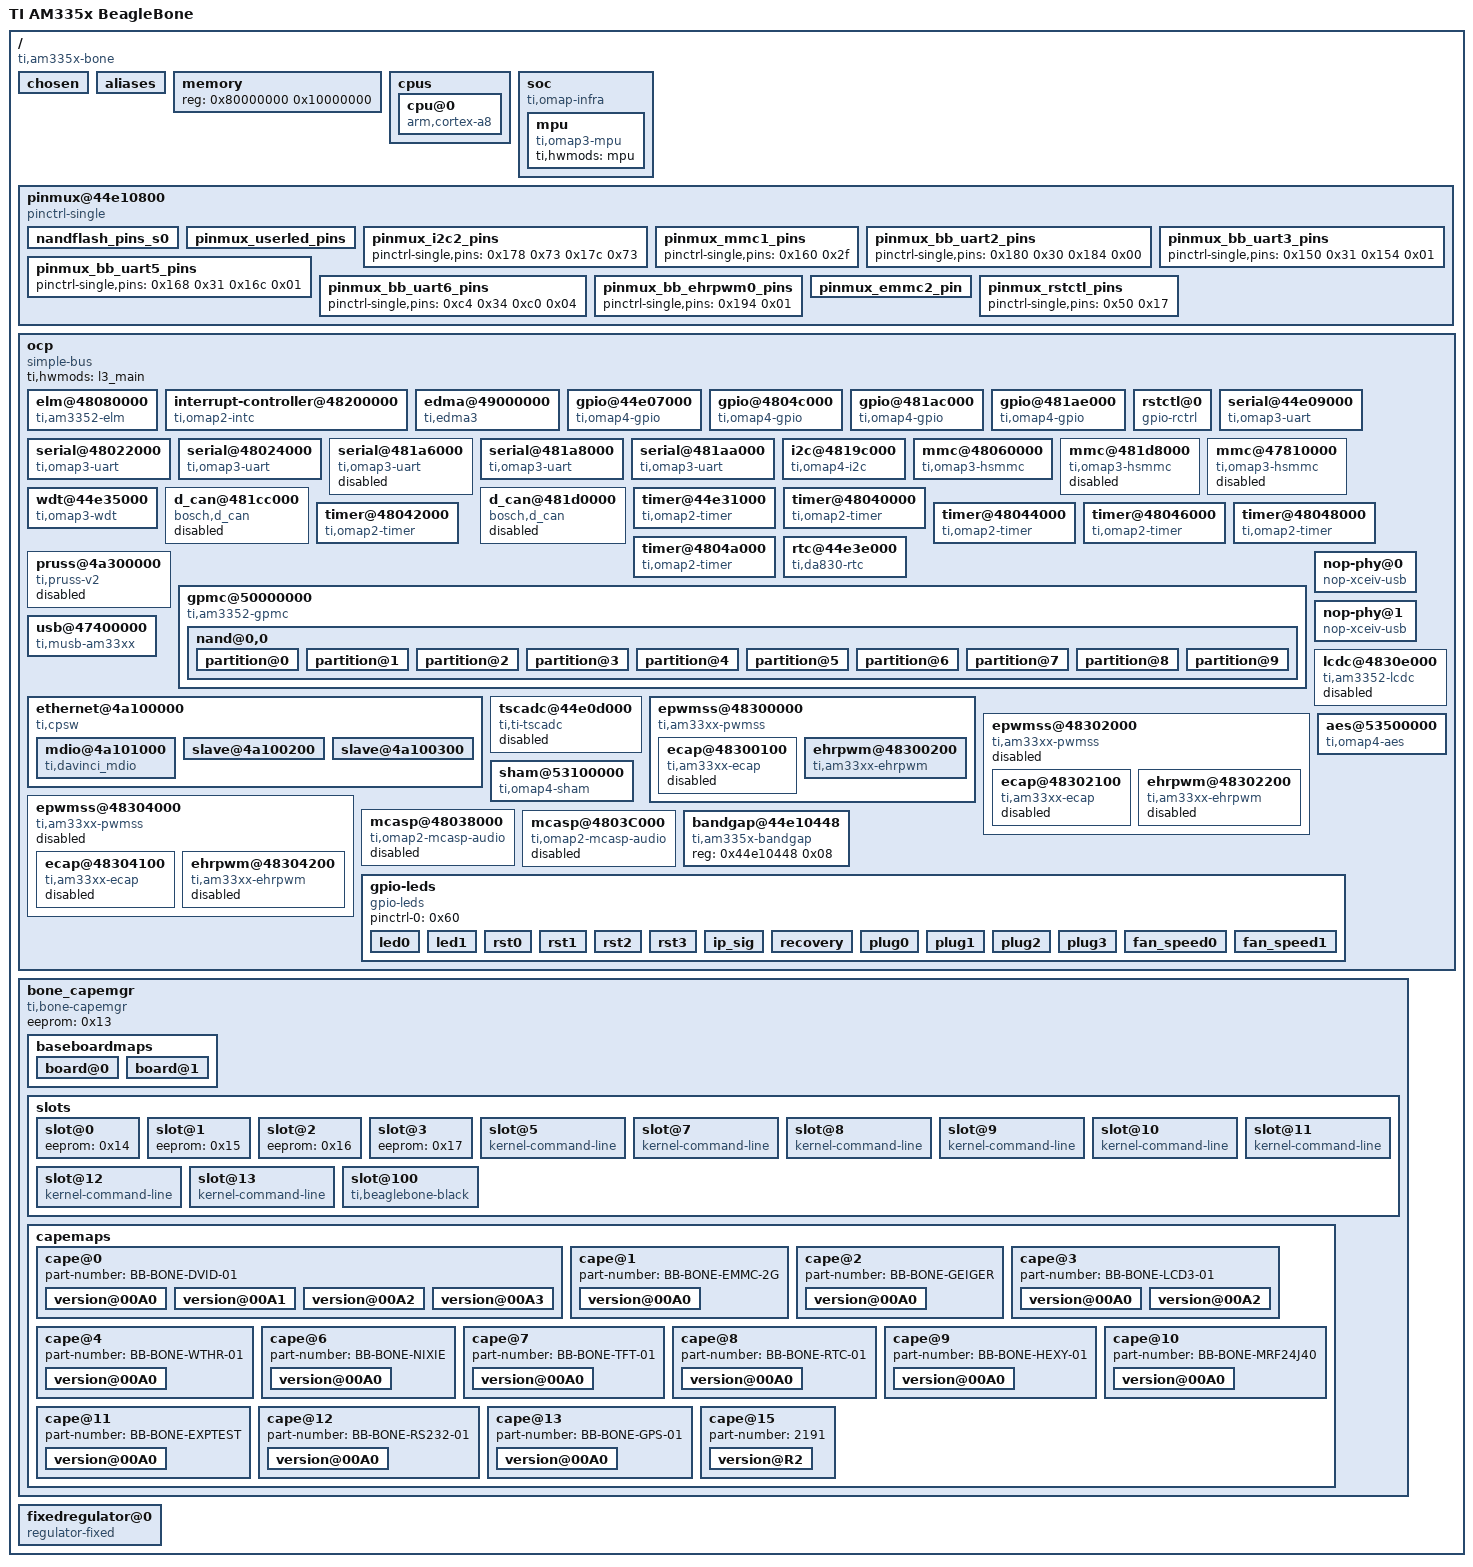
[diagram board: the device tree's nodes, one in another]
/dts-v1/;

/ {
	#address-cells = <0x01>;
	#size-cells = <0x01>;
	compatible = "ti,am335x-bone\0ti,am33xx";
	interrupt-parent = <0x01>;
	model = "TI AM335x BeagleBone";

	chosen {
	};

	aliases {
		serial0 = "/ocp/serial@44e09000";
		serial1 = "/ocp/serial@48022000";
		serial2 = "/ocp/serial@48024000";
		serial3 = "/ocp/serial@481a6000";
		serial4 = "/ocp/serial@481a8000";
		serial5 = "/ocp/serial@481aa000";
	};

	memory {
		device_type = "memory";
		reg = <0x80000000 0x10000000>;
	};

	cpus {

		cpu@0 {
			compatible = "arm,cortex-a8";
			operating-points = <0xf4240 0x149970 0xc3500 0x13d620 0x927c0 0x10f7c0 0x493e0 0xec928>;
			voltage-tolerance = <0x02>;
			clock-latency = <0x493e0>;
			cpu0-supply = <0x02>;
		};
	};

	soc {
		compatible = "ti,omap-infra";

		mpu {
			compatible = "ti,omap3-mpu";
			ti,hwmods = "mpu";
		};
	};

	pinmux@44e10800 {
		compatible = "pinctrl-single";
		reg = <0x44e10800 0x238>;
		#address-cells = <0x01>;
		#size-cells = <0x00>;
		pinctrl-single,register-width = <0x20>;
		pinctrl-single,function-mask = <0x7f>;
		pinctrl-names = "default";
		pinctrl-0 = <0x03>;

		nandflash_pins_s0 {
			pinctrl-single,pins = <0x00 0x30 0x04 0x30 0x08 0x30 0x0c 0x30 0x10 0x30 0x14 0x30 0x18 0x30 0x1c 0x30 0x70 0x30 0x74 0x37 0x7c 0x08 0x90 0x08 0x94 0x08 0x98 0x08 0x9c 0x08>;
		};

		pinmux_userled_pins {
			pinctrl-single,pins = <0x24 0x27 0x34 0x27 0x158 0x27 0x15c 0x27 0x20 0x27 0x2c 0x27 0x28 0x37 0x38 0x37 0x4c 0x27 0x40 0x27 0x3c 0x27 0x30 0x27 0x198 0x27 0x190 0x27>;
			linux,phandle = <0x60>;
			phandle = <0x60>;
		};

		pinmux_i2c2_pins {
			pinctrl-single,pins = <0x178 0x73 0x17c 0x73>;
			linux,phandle = <0x07>;
			phandle = <0x07>;
		};

		pinmux_mmc1_pins {
			pinctrl-single,pins = <0x160 0x2f>;
			linux,phandle = <0x0a>;
			phandle = <0x0a>;
		};

		pinmux_bb_uart2_pins {
			pinctrl-single,pins = <0x180 0x30 0x184 0x00>;
			linux,phandle = <0x51>;
			phandle = <0x51>;
		};

		pinmux_bb_uart3_pins {
			pinctrl-single,pins = <0x150 0x31 0x154 0x01>;
			linux,phandle = <0x52>;
			phandle = <0x52>;
		};

		pinmux_bb_uart5_pins {
			pinctrl-single,pins = <0x168 0x31 0x16c 0x01>;
			linux,phandle = <0x53>;
			phandle = <0x53>;
		};

		pinmux_bb_uart6_pins {
			pinctrl-single,pins = <0xc4 0x34 0xc0 0x04>;
			linux,phandle = <0x54>;
			phandle = <0x54>;
		};

		pinmux_bb_ehrpwm0_pins {
			pinctrl-single,pins = <0x194 0x01>;
			linux,phandle = <0x64>;
			phandle = <0x64>;
		};

		pinmux_emmc2_pin {
			pinctrl-single,pins = <0x80 0x32 0x84 0x32 0x00 0x31 0x04 0x31 0x08 0x31 0x0c 0x31 0x10 0x31 0x14 0x31 0x18 0x31 0x1c 0x31>;
			linux,phandle = <0x0d>;
			phandle = <0x0d>;
		};

		pinmux_rstctl_pins {
			pinctrl-single,pins = <0x50 0x17>;
			linux,phandle = <0x04>;
			phandle = <0x04>;
		};
	};

	ocp {
		compatible = "simple-bus";
		#address-cells = <0x01>;
		#size-cells = <0x01>;
		ranges;
		ti,hwmods = "l3_main";

		elm@48080000 {
			compatible = "ti,am3352-elm";
			reg = <0x48080000 0x2000>;
			interrupts = <0x04>;
			ti,hwmods = "elm";
			clock-names = "fck";
			status = "okay";
			linux,phandle = <0x10>;
			phandle = <0x10>;
		};

		interrupt-controller@48200000 {
			compatible = "ti,omap2-intc";
			interrupt-controller;
			#interrupt-cells = <0x01>;
			ti,intc-size = <0x80>;
			reg = <0x48200000 0x1000>;
			linux,phandle = <0x01>;
			phandle = <0x01>;
		};

		edma@49000000 {
			compatible = "ti,edma3";
			ti,hwmods = "tpcc\0tptc0\0tptc1\0tptc2";
			reg = <0x49000000 0x10000 0x44e10f90 0x40>;
			interrupt-parent = <0x01>;
			interrupts = <0x0c 0x0d 0x0e>;
			#dma-cells = <0x01>;
			dma-channels = <0x40>;
			ti,edma-regions = <0x04>;
			ti,edma-slots = <0x100>;
			ti,edma-queue-tc-map = <0x00 0x00 0x01 0x01 0x02 0x02>;
			ti,edma-queue-priority-map = <0x00 0x00 0x01 0x01 0x02 0x02>;
			ti,edma-default-queue = <0x01>;
			ti,edma-xbar-event-map = <0x20 0x0c 0x1e 0x14>;
			linux,phandle = <0x09>;
			phandle = <0x09>;
		};

		gpio@44e07000 {
			compatible = "ti,omap4-gpio";
			ti,hwmods = "gpio1";
			gpio-controller;
			#gpio-cells = <0x02>;
			interrupt-controller;
			#interrupt-cells = <0x01>;
			reg = <0x44e07000 0x1000>;
			interrupts = <0x60>;
			linux,phandle = <0x0b>;
			phandle = <0x0b>;
		};

		gpio@4804c000 {
			compatible = "ti,omap4-gpio";
			ti,hwmods = "gpio2";
			gpio-controller;
			#gpio-cells = <0x02>;
			interrupt-controller;
			#interrupt-cells = <0x01>;
			reg = <0x4804c000 0x1000>;
			interrupts = <0x62>;
			linux,phandle = <0x05>;
			phandle = <0x05>;
		};

		gpio@481ac000 {
			compatible = "ti,omap4-gpio";
			ti,hwmods = "gpio3";
			gpio-controller;
			#gpio-cells = <0x02>;
			interrupt-controller;
			#interrupt-cells = <0x01>;
			reg = <0x481ac000 0x1000>;
			interrupts = <0x20>;
			linux,phandle = <0x70>;
			phandle = <0x70>;
		};

		gpio@481ae000 {
			compatible = "ti,omap4-gpio";
			ti,hwmods = "gpio4";
			gpio-controller;
			#gpio-cells = <0x02>;
			interrupt-controller;
			#interrupt-cells = <0x01>;
			reg = <0x481ae000 0x1000>;
			interrupts = <0x3e>;
			linux,phandle = <0x71>;
			phandle = <0x71>;
		};

		rstctl@0 {
			status = "okay";
			compatible = "gpio-rctrl";
			pinctrl-names = "default";
			pinctrl-0 = <0x04>;
			#reset-cells = <0x02>;
			gpios = <0x05 0x14 0x00>;
			gpio-names = "eMMC_RSTn";
			linux,phandle = <0x0f>;
			phandle = <0x0f>;
		};

		serial@44e09000 {
			compatible = "ti,omap3-uart";
			ti,hwmods = "uart1";
			clock-frequency = <0x2dc6c00>;
			reg = <0x44e09000 0x2000>;
			interrupts = <0x48>;
			status = "okay";
		};

		serial@48022000 {
			compatible = "ti,omap3-uart";
			ti,hwmods = "uart2";
			clock-frequency = <0x2dc6c00>;
			reg = <0x48022000 0x2000>;
			interrupts = <0x49>;
			status = "okay";
			pinctrl-names = "default";
			pinctrl-0 = <0x51>;
		};

		serial@48024000 {
			compatible = "ti,omap3-uart";
			ti,hwmods = "uart3";
			clock-frequency = <0x2dc6c00>;
			reg = <0x48024000 0x2000>;
			interrupts = <0x4a>;
			status = "okay";
			pinctrl-names = "default";
			pinctrl-0 = <0x52>;
		};

		serial@481a6000 {
			compatible = "ti,omap3-uart";
			ti,hwmods = "uart4";
			clock-frequency = <0x2dc6c00>;
			reg = <0x481a6000 0x2000>;
			interrupts = <0x2c>;
			status = "disabled";
		};

		serial@481a8000 {
			compatible = "ti,omap3-uart";
			ti,hwmods = "uart5";
			clock-frequency = <0x2dc6c00>;
			reg = <0x481a8000 0x2000>;
			interrupts = <0x2d>;
			status = "okay";
			pinctrl-names = "default";
			pinctrl-0 = <0x53>;
		};

		serial@481aa000 {
			compatible = "ti,omap3-uart";
			ti,hwmods = "uart6";
			clock-frequency = <0x2dc6c00>;
			reg = <0x481aa000 0x2000>;
			interrupts = <0x2e>;
			status = "okay";
			pinctrl-names = "default";
			pinctrl-0 = <0x54>;
		};

		i2c@4819c000 {
			compatible = "ti,omap4-i2c";
			#address-cells = <0x01>;
			#size-cells = <0x00>;
			ti,hwmods = "i2c3";
			reg = <0x4819c000 0x1000>;
			interrupts = <0x1e>;
			status = "okay";
			pinctrl-names = "default";
			pinctrl-0 = <0x07>;
			clock-frequency = <0x186a0>;
		};

		mmc@48060000 {
			compatible = "ti,omap3-hsmmc";
			ti,hwmods = "mmc1";
			ti,dual-volt;
			ti,needs-special-reset;
			ti,needs-special-hs-handling;
			dmas = <0x09 0x18 0x09 0x19>;
			dma-names = "tx\0rx";
			status = "okay";
			pinctrl-names = "default";
			pinctrl-0 = <0x0a>;
			cd-gpios = <0x0b 0x06 0x00>;
			cd-inverted;
			vmmc-supply = <0x0c>;
			ti,vcc-aux-disable-is-sleep;
		};

		mmc@481d8000 {
			compatible = "ti,omap3-hsmmc";
			ti,hwmods = "mmc2";
			ti,needs-special-reset;
			ti,needs-special-hs-handling;
			dmas = <0x09 0x02 0x09 0x03>;
			dma-names = "tx\0rx";
			status = "disabled";
		};

		mmc@47810000 {
			compatible = "ti,omap3-hsmmc";
			ti,hwmods = "mmc3";
			ti,needs-special-reset;
			ti,needs-special-hs-handling;
			status = "disabled";
		};

		wdt@44e35000 {
			compatible = "ti,omap3-wdt";
			ti,hwmods = "wd_timer2";
			reg = <0x44e35000 0x1000>;
			interrupts = <0x5b>;
		};

		d_can@481cc000 {
			compatible = "bosch,d_can";
			ti,hwmods = "d_can0";
			reg = <0x481cc000 0x2000>;
			interrupts = <0x34>;
			status = "disabled";
		};

		d_can@481d0000 {
			compatible = "bosch,d_can";
			ti,hwmods = "d_can1";
			reg = <0x481d0000 0x2000>;
			interrupts = <0x37>;
			status = "disabled";
		};

		timer@44e31000 {
			compatible = "ti,omap2-timer";
			reg = <0x44e31000 0x400>;
			interrupts = <0x43>;
			ti,hwmods = "timer1";
			ti,timer-alwon;
		};

		timer@48040000 {
			compatible = "ti,omap2-timer";
			reg = <0x48040000 0x400>;
			interrupts = <0x44>;
			ti,hwmods = "timer2";
		};

		timer@48042000 {
			compatible = "ti,omap2-timer";
			reg = <0x48042000 0x400>;
			interrupts = <0x45>;
			ti,hwmods = "timer3";
		};

		timer@48044000 {
			compatible = "ti,omap2-timer";
			reg = <0x48044000 0x400>;
			interrupts = <0x5c>;
			ti,hwmods = "timer4";
			ti,timer-pwm;
		};

		timer@48046000 {
			compatible = "ti,omap2-timer";
			reg = <0x48046000 0x400>;
			interrupts = <0x5d>;
			ti,hwmods = "timer5";
			ti,timer-pwm;
		};

		timer@48048000 {
			compatible = "ti,omap2-timer";
			reg = <0x48048000 0x400>;
			interrupts = <0x5e>;
			ti,hwmods = "timer6";
			ti,timer-pwm;
		};

		timer@4804a000 {
			compatible = "ti,omap2-timer";
			reg = <0x4804a000 0x400>;
			interrupts = <0x5f>;
			ti,hwmods = "timer7";
			ti,timer-pwm;
		};

		pruss@4a300000 {
			compatible = "ti,pruss-v2";
			ti,hwmods = "pruss";
			ti,deassert-hard-reset = "pruss\0pruss";
			reg = <0x4a300000 0x80000>;
			ti,pintc-offset = <0x20000>;
			interrupt-parent = <0x01>;
			status = "disabled";
			interrupts = <0x14 0x15 0x16 0x17 0x18 0x19 0x1a 0x1b>;
		};

		rtc@44e3e000 {
			compatible = "ti,da830-rtc";
			reg = <0x44e3e000 0x1000>;
			interrupts = <0x4b 0x4c>;
			ti,hwmods = "rtc";
			ti,system-power-controller;
		};

		gpmc@50000000 {
			compatible = "ti,am3352-gpmc";
			ti,hwmods = "gpmc";
			reg = <0x50000000 0x1000000>;
			interrupts = <0x64>;
			gpmc,num-cs = <0x07>;
			gpmc,num-waitpins = <0x02>;
			#address-cells = <0x02>;
			#size-cells = <0x01>;
			status = "okay";
			pinctrl-names = "default";
			pinctrl-0 = <0x0f>;
			ranges = <0x00 0x00 0x8000000 0x10000000>;

			nand@0,0 {
				gpmc,device-nand;
				reg = <0x00 0x00 0x00>;
				nand-bus-width = <0x08>;
				gpmc,device-width = <0x01>;
				gpmc,sync-clk-ps = <0x00>;
				gpmc,cs-on-ns = <0x00>;
				gpmc,cs-rd-off-ns = <0x118>;
				gpmc,cs-wr-off-ns = <0x118>;
				gpmc,adv-on-ns = <0x32>;
				gpmc,adv-rd-off-ns = <0x118>;
				gpmc,adv-wr-off-ns = <0x118>;
				gpmc,we-on-ns = <0x32>;
				gpmc,we-off-ns = <0xc8>;
				gpmc,oe-on-ns = <0x32>;
				gpmc,oe-off-ns = <0x96>;
				gpmc,access-ns = <0xc8>;
				gpmc,rd-cycle-ns = <0x12c>;
				gpmc,wr-cycle-ns = <0x12c>;
				gpmc,wait-on-read = "true";
				gpmc,wait-on-write = "true";
				gpmc,bus-turnaround-ns = <0x00>;
				gpmc,cycle2cycle-delay-ns = <0x78>;
				gpmc,cycle2cycle-samecsen = "true";
				gpmc,clk-activation-ns = <0x00>;
				gpmc,wait-monitoring-ns = <0x00>;
				gpmc,wr-access-ns = <0x28>;
				gpmc,wr-data-mux-bus-ns = <0x00>;
				ti,nand-ecc-opt = "bch8";
				ti,elm-id = <0x10>;
				#address-cells = <0x01>;
				#size-cells = <0x01>;

				partition@0 {
					label = "spl";
					reg = <0x00 0x20000>;
				};

				partition@1 {
					label = "spl_backup1";
					reg = <0x20000 0x20000>;
				};

				partition@2 {
					label = "spl_backup2";
					reg = <0x40000 0x20000>;
				};

				partition@3 {
					label = "spl_backup3";
					reg = <0x60000 0x20000>;
				};

				partition@4 {
					label = "u-boot";
					reg = <0x80000 0x1c0000>;
				};

				partition@5 {
					label = "bootenv";
					reg = <0x240000 0x20000>;
				};

				partition@6 {
					label = "fdt";
					reg = <0x260000 0x20000>;
				};

				partition@7 {
					label = "kernel";
					reg = <0x280000 0x500000>;
				};

				partition@8 {
					label = "root";
					reg = <0x800000 0x1400000>;
				};

				partition@9 {
					label = "config";
					reg = <0x1c00000 0x1400000>;
				};
			};
		};

		nop-phy@0 {
			compatible = "nop-xceiv-usb";
		};

		nop-phy@1 {
			compatible = "nop-xceiv-usb";
		};

		usb@47400000 {
			compatible = "ti,musb-am33xx";
			reg = <0x47400000 0x1000 0x47401000 0x800 0x47401800 0x800>;
			interrupts = <0x11 0x12 0x13>;
			multipoint = <0x01>;
			num-eps = <0x10>;
			ram-bits = <0x0c>;
			port0-mode = <0x03>;
			port1-mode = <0x01>;
			power = <0xfa>;
			ti,hwmods = "usb_otg_hs";
			status = "okay";
			interface_type = <0x01>;
		};

		ethernet@4a100000 {
			compatible = "ti,cpsw";
			ti,hwmods = "cpgmac0";
			cpdma_channels = <0x08>;
			ale_entries = <0x400>;
			bd_ram_size = <0x2000>;
			no_bd_ram = <0x00>;
			rx_descs = <0x40>;
			mac_control = <0x20>;
			slaves = <0x02>;
			cpts_active_slave = <0x00>;
			cpts_clock_mult = <0x80000000>;
			cpts_clock_shift = <0x1d>;
			reg = <0x4a100000 0x800 0x4a101200 0x100>;
			#address-cells = <0x01>;
			#size-cells = <0x01>;
			interrupt-parent = <0x01>;
			interrupts = <0x28 0x29 0x2a 0x2b>;
			ranges;
			disable-napi;

			mdio@4a101000 {
				compatible = "ti,davinci_mdio";
				#address-cells = <0x01>;
				#size-cells = <0x00>;
				ti,hwmods = "davinci_mdio";
				bus_freq = <0xf4240>;
				reg = <0x4a101000 0x100>;
				linux,phandle = <0x12>;
				phandle = <0x12>;
			};

			slave@4a100200 {
				mac-address = [00 00 00 00 00 00];
				phy_id = <0x12 0x00>;
			};

			slave@4a100300 {
				mac-address = [00 00 00 00 00 00];
				phy_id = <0x12 0x01>;
			};
		};

		tscadc@44e0d000 {
			compatible = "ti,ti-tscadc";
			reg = <0x44e0d000 0x1000>;
			interrupt-parent = <0x01>;
			interrupts = <0x10>;
			ti,hwmods = "adc_tsc";
			status = "disabled";
		};

		lcdc@4830e000 {
			compatible = "ti,am3352-lcdc\0ti,da830-lcdc";
			reg = <0x4830e000 0x1000>;
			interrupts = <0x24>;
			status = "disabled";
			ti,hwmods = "lcdc";
		};

		epwmss@48300000 {
			compatible = "ti,am33xx-pwmss";
			reg = <0x48300000 0x10>;
			ti,hwmods = "epwmss0";
			#address-cells = <0x01>;
			#size-cells = <0x01>;
			status = "okay";
			ranges = <0x48300100 0x48300100 0x80 0x48300180 0x48300180 0x80 0x48300200 0x48300200 0x80>;

			ecap@48300100 {
				compatible = "ti,am33xx-ecap";
				#pwm-cells = <0x03>;
				reg = <0x48300100 0x80>;
				ti,hwmods = "ecap0";
				status = "disabled";
			};

			ehrpwm@48300200 {
				compatible = "ti,am33xx-ehrpwm";
				#pwm-cells = <0x03>;
				reg = <0x48300200 0x60>;
				ti,hwmods = "ehrpwm0";
				status = "okay";
				pinctrl-names = "default";
				pinctrl-0 = <0x64>;
			};
		};

		epwmss@48302000 {
			compatible = "ti,am33xx-pwmss";
			reg = <0x48302000 0x10>;
			ti,hwmods = "epwmss1";
			#address-cells = <0x01>;
			#size-cells = <0x01>;
			status = "disabled";
			ranges = <0x48302100 0x48302100 0x80 0x48302180 0x48302180 0x80 0x48302200 0x48302200 0x80>;

			ecap@48302100 {
				compatible = "ti,am33xx-ecap";
				#pwm-cells = <0x03>;
				reg = <0x48302100 0x80>;
				ti,hwmods = "ecap1";
				status = "disabled";
			};

			ehrpwm@48302200 {
				compatible = "ti,am33xx-ehrpwm";
				#pwm-cells = <0x03>;
				reg = <0x48302200 0x80>;
				ti,hwmods = "ehrpwm1";
				status = "disabled";
			};
		};

		epwmss@48304000 {
			compatible = "ti,am33xx-pwmss";
			reg = <0x48304000 0x10>;
			ti,hwmods = "epwmss2";
			#address-cells = <0x01>;
			#size-cells = <0x01>;
			status = "disabled";
			ranges = <0x48304100 0x48304100 0x80 0x48304180 0x48304180 0x80 0x48304200 0x48304200 0x80>;

			ecap@48304100 {
				compatible = "ti,am33xx-ecap";
				#pwm-cells = <0x03>;
				reg = <0x48304100 0x80>;
				ti,hwmods = "ecap2";
				status = "disabled";
			};

			ehrpwm@48304200 {
				compatible = "ti,am33xx-ehrpwm";
				#pwm-cells = <0x03>;
				reg = <0x48304200 0x80>;
				ti,hwmods = "ehrpwm2";
				status = "disabled";
			};
		};

		sham@53100000 {
			compatible = "ti,omap4-sham";
			ti,hwmods = "sham";
			#address-cells = <0x01>;
			#size-cells = <0x00>;
			reg = <0x53100000 0x200>;
			interrupt-parent = <0x01>;
			interrupts = <0x6d>;
			dmas = <0x09 0x24>;
			dma-names = "rx";
			status = "okay";
		};

		aes@53500000 {
			compatible = "ti,omap4-aes";
			ti,hwmods = "aes";
			#address-cells = <0x01>;
			#size-cells = <0x00>;
			reg = <0x53500000 0xa0>;
			interrupt-parent = <0x01>;
			interrupts = <0x66>;
			dmas = <0x09 0x06 0x09 0x05>;
			dma-names = "tx\0rx";
			status = "okay";
		};

		mcasp@48038000 {
			compatible = "ti,omap2-mcasp-audio";
			#address-cells = <0x01>;
			#size-cells = <0x00>;
			ti,hwmods = "mcasp0";
			reg = <0x48038000 0x2000>;
			interrupts = <0x50 0x51>;
			status = "disabled";
			asp-chan-q = <0x02>;
			tx-dma-offset = <0x46000000>;
			rx-dma-offset = <0x46000000>;
			dmas = <0x09 0x08 0x09 0x09>;
			dma-names = "tx\0rx";
		};

		mcasp@4803C000 {
			compatible = "ti,omap2-mcasp-audio";
			#address-cells = <0x01>;
			#size-cells = <0x00>;
			ti,hwmods = "mcasp1";
			reg = <0x4803c000 0x2000>;
			interrupts = <0x52 0x53>;
			status = "disabled";
			asp-chan-q = <0x02>;
			tx-dma-offset = "F@\0";
			rx-dma-offset = "F@\0";
			dmas = <0x09 0x0a 0x09 0x0b>;
			dma-names = "tx\0rx";
		};

		bandgap@44e10448 {
			compatible = "ti,am335x-bandgap";
			reg = <0x44e10448 0x08>;
		};

		gpio-leds {
			compatible = "gpio-leds";
			pinctrl-names = "default";
			pinctrl-0 = <0x60>;

			led0 {
				label = "Green";
				gpios = <0x0b 0x23 0x01>;
				default-state = "on";
			};

			led1 {
				label = "Red";
				gpios = <0x05 0x13 0x01>;
				default-state = "on";
			};

			rst0 {
				label = "rst0";
				gpios = <0x0b 0x05 0x01>;
				default-state = "on";
			};

			rst1 {
				label = "res1";
				gpios = <0x0b 0x04 0x01>;
				default-state = "on";
			};

			rst2 {
				label = "rst2";
				gpios = <0x0b 0x27 0x01>;
				default-state = "on";
			};

			rst3 {
				label = "rst3";
				gpios = <0x0b 0x22 0x01>;
				default-state = "on";
			};

			ip_sig {
				label = "ip_sig";
				gpios = <0x0b 0x26 0x01>;
				default-state = "on";
			};

			recovery {
				label = "recovery";
				gpios = <0x05 0x14 0x01>;
				default-state = "on";
			};

			plug0 {
				label = "plug0";
				gpios = <0x05 0x26 0x01>;
				default-state = "on";
			};

			plug1 {
				label = "plug1";
				gpios = <0x05 0x16 0x01>;
				default-state = "on";
			};

			plug2 {
				label = "plug2";
				gpios = <0x05 0x15 0x01>;
				default-state = "on";
			};

			plug3 {
				label = "plug0";
				gpios = <0x05 0x12 0x01>;
				default-state = "on";
			};

			fan_speed0 {
				label = "fan_speed0";
				gpios = <0x71 0x15 0x01>;
				default-state = "on";
			};

			fan_speed1 {
				label = "fan_speed1";
				gpios = <0x71 0x14 0x01>;
				default-state = "on";
			};
		};
	};

	bone_capemgr {
		compatible = "ti,bone-capemgr";
		status = "okay";
		eeprom = <0x13>;

		baseboardmaps {

			board@0 {
				board-name = "A335BONE";
				compatible-name = "ti,beaglebone";
			};

			board@1 {
				board-name = "A335BNLT";
				compatible-name = "ti,beaglebone-black";
			};
		};

		slots {

			slot@0 {
				eeprom = <0x14>;
			};

			slot@1 {
				eeprom = <0x15>;
			};

			slot@2 {
				eeprom = <0x16>;
			};

			slot@3 {
				eeprom = <0x17>;
			};

			slot@5 {
				ti,cape-override;
				compatible = "kernel-command-line\0runtime";
				board-name = "Bone-Geiger";
				version = "00A0";
				manufacturer = "Geiger Inc.";
				part-number = "BB-BONE-GEIGER";
			};

			slot@7 {
				ti,cape-override;
				compatible = "kernel-command-line\0runtime";
				board-name = "Bone-Nixie";
				version = "00A0";
				manufacturer = "Ranostay Industries";
				part-number = "BB-BONE-NIXIE";
			};

			slot@8 {
				ti,cape-override;
				compatible = "kernel-command-line\0runtime";
				board-name = "Bone-TFT";
				version = "00A0";
				manufacturer = "Adafruit";
				part-number = "BB-BONE-TFT-01";
			};

			slot@9 {
				ti,cape-override;
				compatible = "kernel-command-line\0runtime";
				board-name = "Bone-RTC";
				version = "00A0";
				manufacturer = "Adafruit";
				part-number = "BB-BONE-RTC-01";
			};

			slot@10 {
				ti,cape-override;
				compatible = "kernel-command-line\0runtime";
				board-name = "Bone-Hexy";
				version = "00A0";
				manufacturer = "Koen Kooi";
				part-number = "BB-BONE-HEXY-01";
			};

			slot@11 {
				ti,cape-override;
				compatible = "kernel-command-line\0runtime";
				board-name = "Bone-MRF24J40";
				version = "00A0";
				manufacturer = "Signal 11 Software";
				part-number = "BB-BONE-MRF24J40";
			};

			slot@12 {
				ti,cape-override;
				compatible = "kernel-command-line\0runtime";
				board-name = "BB-BONE-RS232";
				version = "00A0";
				manufacturer = "Adafruit";
				part-number = "BB-BONE-RS232-01";
			};

			slot@13 {
				compatible = "kernel-command-line\0runtime";
				board-name = "BB-BONE-GPS";
				version = "00A0";
				manufacturer = "Adafruit";
				part-number = "BB-BONE-GPS-01";
			};

			slot@100 {
				ti,cape-override;
				priority = <0x01>;
				compatible = "ti,beaglebone-black";
				board-name = "Bone-LT-eMMC-2G";
				version = "00A0";
				manufacturer = "Texas Instruments";
				part-number = "BB-BONE-EMMC-2G";
			};
		};

		capemaps {

			cape@0 {
				part-number = "BB-BONE-DVID-01";

				version@00A0 {
					version = "00A0";
					dtbo = "cape-bone-dvi-00A0.dtbo";
				};

				version@00A1 {
					version = "00A1\001";
					dtbo = "cape-bone-dvi-00A1.dtbo";
				};

				version@00A2 {
					version = "00A2\0A2";
					dtbo = "cape-bone-dvi-00A2.dtbo";
				};

				version@00A3 {
					version = "00A3";
					dtbo = "cape-bone-dvi-00A2.dtbo";
				};
			};

			cape@1 {
				part-number = "BB-BONE-EMMC-2G";

				version@00A0 {
					version = "00A0";
					dtbo = "cape-bone-2g-emmc1.dtbo";
				};
			};

			cape@2 {
				part-number = "BB-BONE-GEIGER";

				version@00A0 {
					version = "00A0";
					dtbo = "cape-bone-geiger-00A0.dtbo";
				};
			};

			cape@3 {
				part-number = "BB-BONE-LCD3-01";

				version@00A0 {
					version = "00A0";
					dtbo = "cape-bone-lcd3-00A0.dtbo";
				};

				version@00A2 {
					version = "00A2";
					dtbo = "cape-bone-lcd3-00A2.dtbo";
				};
			};

			cape@4 {
				part-number = "BB-BONE-WTHR-01";

				version@00A0 {
					version = "00A0";
					dtbo = "cape-bone-weather-00A0.dtbo";
				};
			};

			cape@6 {
				part-number = "BB-BONE-NIXIE";

				version@00A0 {
					version = "00A0";
					dtbo = "cape-bone-nixie-00A0.dtbo";
				};
			};

			cape@7 {
				part-number = "BB-BONE-TFT-01";

				version@00A0 {
					version = "00A0";
					dtbo = "cape-bone-adafruit-lcd-00A0.dtbo";
				};
			};

			cape@8 {
				part-number = "BB-BONE-RTC-01";

				version@00A0 {
					version = "00A0";
					dtbo = "BB-BONE-RTC-00A0.dtbo";
				};
			};

			cape@9 {
				part-number = "BB-BONE-HEXY-01";

				version@00A0 {
					version = "00A0";
					dtbo = "cape-bone-hexy-00A0.dtbo";
				};
			};

			cape@10 {
				part-number = "BB-BONE-MRF24J40";

				version@00A0 {
					version = "00A0";
					dtbo = "cape-bone-mrf24j40-00A0.dtbo";
				};
			};

			cape@11 {
				part-number = "BB-BONE-EXPTEST";

				version@00A0 {
					version = "00A0";
					dtbo = "cape-bone-exptest-00A0.dtbo";
				};
			};

			cape@12 {
				part-number = "BB-BONE-RS232-01";

				version@00A0 {
					version = "00A0";
					dtbo = "BB-BONE-RS232-00A0.dtbo";
				};
			};

			cape@13 {
				part-number = "BB-BONE-GPS-01";

				version@00A0 {
					version = "00A0";
					dtbo = "BB-BONE-GPS-00A0.dtbo";
				};
			};

			cape@15 {
				part-number = "2191";

				version@R2 {
					version = "R2";
					dtbo = "cape-bebopr-R2.dtbo";
				};
			};
		};
	};

	fixedregulator@0 {
		compatible = "regulator-fixed";
		regulator-name = "vmmcsd_fixed";
		regulator-min-microvolt = <0x325aa0>;
		regulator-max-microvolt = <0x325aa0>;
		linux,phandle = <0x0c>;
		phandle = <0x0c>;
	};
};
